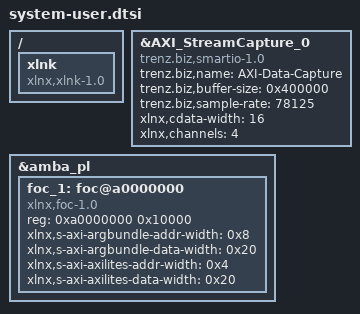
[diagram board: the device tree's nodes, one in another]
/include/ "system-conf.dtsi"
/ {

  /* Added for SDSoC flow */
   xlnk {
      compatible = "xlnx,xlnk-1.0";
   };

/*
	aliases {
		serial0 = &uart0;
		serial1 = &uart1;
	};
*/

};

/* Added if using HLS flow */
/*
&axi_reg32_0 {
   compatible = "trenz.biz,smartio-1.0";
   trenz.biz,name = "foc";
};
*/


&AXI_StreamCapture_0 {
   compatible = "trenz.biz,smartio-1.0";
   trenz.biz,name = "AXI-Data-Capture";
   trenz.biz,buffer-size = <0x400000>;
   trenz.biz,sample-rate = <78125>;
   xlnx,cdata-width = <16>;
   xlnx,channels = <4>;
};


&amba_pl {
      /* FocDevice.cpp:132 looks for this device */

      foc_1: foc@a0000000 {
         compatible = "xlnx,foc-1.0";
         
         /* DeviceTreeDevice.cpp DeviceTreeDevice::findByProperty() only expects 2
          * values in reg as defined by (uint32_t	p_reg[2]) and will core dump if 4
          * values are in reg. By changing src to p_reg[4] the core dump can be prevented
          * or in this case, will reduce the reg entries to 2.
          *
          * Note that second address/range appears to be related to the axi capture dma
          */
         /*
         reg = <0xa0000000 0x10000 0xa0010000 0x10000>; 
         */

         reg = <0xa0000000 0x10000>; 

         xlnx,s-axi-argbundle-addr-width = <0x8>;
         xlnx,s-axi-argbundle-data-width = <0x20>;
         xlnx,s-axi-axilites-addr-width = <0x4>;
         xlnx,s-axi-axilites-data-width = <0x20>;
      };
};

